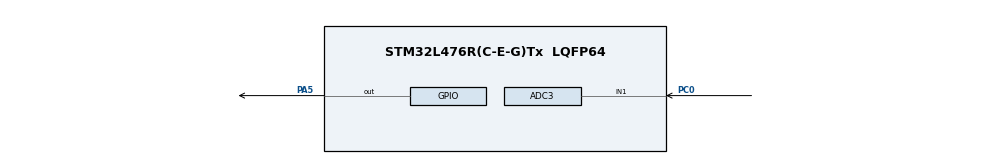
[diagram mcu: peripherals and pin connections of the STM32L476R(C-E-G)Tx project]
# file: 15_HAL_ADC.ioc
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ADC3.Channel-0\#ChannelRegularConversion=ADC_CHANNEL_1
ADC3.ContinuousConvMode=ENABLE
ADC3.NbrOfConversionFlag=1
ADC3.OffsetNumber-0\#ChannelRegularConversion=ADC_OFFSET_NONE
ADC3.Rank-0\#ChannelRegularConversion=1
ADC3.SamplingTime-0\#ChannelRegularConversion=ADC_SAMPLETIME_2CYCLES_5
Mcu.Family=STM32L4
Mcu.Name=STM32L476R(C-E-G)Tx
Mcu.Package=LQFP64
NVIC.PriorityGroup=NVIC_PRIORITYGROUP_4
PA5.Signal=GPIO_Output
PC0.Signal=ADCx_IN1
ProjectManager.HeapSize=0x200
ProjectManager.StackSize=0x400
ProjectManager.TargetToolchain=STM32CubeIDE
RCC.HSE_VALUE=8000000
RCC.HSI_VALUE=16000000
RCC.LSE_VALUE=32768
RCC.MSI_VALUE=4000000
RCC.VCOOutputFreq_Value=32000000
SH.ADCx_IN1.0=ADC3_IN1,IN1-Single-Ended
board=custom

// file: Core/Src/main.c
/* USER CODE BEGIN Header */
/**
  ******************************************************************************
  * @file           : main.c
  * @brief          : Main program body
  ******************************************************************************
  * @attention
  *
  * Copyright (c) 2026 STMicroelectronics.
  * All rights reserved.
  *
  * This software is licensed under terms that can be found in the LICENSE file
  * in the root directory of this software component.
  * If no LICENSE file comes with this software, it is provided AS-IS.
  *
  ******************************************************************************
  */
/* USER CODE END Header */
#include "main.h"

ADC_HandleTypeDef hadc3;

void SystemClock_Config(void);
static void MX_GPIO_Init(void);
static void MX_ADC3_Init(void);

/* USER CODE BEGIN 0 */
uint16_t adc_value = 0;
/* USER CODE END 0 */

int main(void)
{

  /* MCU Configuration--------------------------------------------------------*/

  /* Reset of all peripherals, Initializes the Flash interface and the Systick. */
  HAL_Init();

  /* Configure the system clock */
  SystemClock_Config();

  /* Initialize all configured peripherals */
  MX_GPIO_Init();
  MX_ADC3_Init();
  /* USER CODE BEGIN 2 */
  HAL_ADC_Start(&hadc3);
  /* USER CODE END 2 */

  /* Infinite loop */
  /* USER CODE BEGIN WHILE */
  while (1)
  {

	      HAL_ADC_PollForConversion(&hadc3, HAL_MAX_DELAY);

	      adc_value = HAL_ADC_GetValue(&hadc3);

    /* USER CODE END WHILE */

  }
}

void SystemClock_Config(void)
{
  RCC_OscInitTypeDef RCC_OscInitStruct = {0};
  RCC_ClkInitTypeDef RCC_ClkInitStruct = {0};

  /** Configure the main internal regulator output voltage
  */
  if (HAL_PWREx_ControlVoltageScaling(PWR_REGULATOR_VOLTAGE_SCALE1) != HAL_OK)
  {
    Error_Handler();
  }

  /** Initializes the RCC Oscillators according to the specified parameters
  * in the RCC_OscInitTypeDef structure.
  */
  RCC_OscInitStruct.OscillatorType = RCC_OSCILLATORTYPE_MSI;
  RCC_OscInitStruct.MSIState = RCC_MSI_ON;
  RCC_OscInitStruct.MSICalibrationValue = 0;
  RCC_OscInitStruct.MSIClockRange = RCC_MSIRANGE_6;
  RCC_OscInitStruct.PLL.PLLState = RCC_PLL_NONE;
  if (HAL_RCC_OscConfig(&RCC_OscInitStruct) != HAL_OK)
  {
    Error_Handler();
  }

  /** Initializes the CPU, AHB and APB buses clocks
  */
  RCC_ClkInitStruct.ClockType = RCC_CLOCKTYPE_HCLK|RCC_CLOCKTYPE_SYSCLK
                              |RCC_CLOCKTYPE_PCLK1|RCC_CLOCKTYPE_PCLK2;
  RCC_ClkInitStruct.SYSCLKSource = RCC_SYSCLKSOURCE_MSI;
  RCC_ClkInitStruct.AHBCLKDivider = RCC_SYSCLK_DIV1;
  RCC_ClkInitStruct.APB1CLKDivider = RCC_HCLK_DIV1;
  RCC_ClkInitStruct.APB2CLKDivider = RCC_HCLK_DIV1;

  if (HAL_RCC_ClockConfig(&RCC_ClkInitStruct, FLASH_LATENCY_0) != HAL_OK)
  {
    Error_Handler();
  }
}

static void MX_ADC3_Init(void)
{

  ADC_ChannelConfTypeDef sConfig = {0};

  /** Common config
  */
  hadc3.Instance = ADC3;
  hadc3.Init.ClockPrescaler = ADC_CLOCK_ASYNC_DIV1;
  hadc3.Init.Resolution = ADC_RESOLUTION_12B;
  hadc3.Init.DataAlign = ADC_DATAALIGN_RIGHT;
  hadc3.Init.ScanConvMode = ADC_SCAN_DISABLE;
  hadc3.Init.EOCSelection = ADC_EOC_SINGLE_CONV;
  hadc3.Init.LowPowerAutoWait = DISABLE;
  hadc3.Init.ContinuousConvMode = ENABLE;
  hadc3.Init.NbrOfConversion = 1;
  hadc3.Init.DiscontinuousConvMode = DISABLE;
  hadc3.Init.ExternalTrigConv = ADC_SOFTWARE_START;
  hadc3.Init.ExternalTrigConvEdge = ADC_EXTERNALTRIGCONVEDGE_NONE;
  hadc3.Init.DMAContinuousRequests = DISABLE;
  hadc3.Init.Overrun = ADC_OVR_DATA_PRESERVED;
  hadc3.Init.OversamplingMode = DISABLE;
  if (HAL_ADC_Init(&hadc3) != HAL_OK)
  {
    Error_Handler();
  }

  /** Configure Regular Channel
  */
  sConfig.Channel = ADC_CHANNEL_1;
  sConfig.Rank = ADC_REGULAR_RANK_1;
  sConfig.SamplingTime = ADC_SAMPLETIME_2CYCLES_5;
  sConfig.SingleDiff = ADC_SINGLE_ENDED;
  sConfig.OffsetNumber = ADC_OFFSET_NONE;
  sConfig.Offset = 0;
  if (HAL_ADC_ConfigChannel(&hadc3, &sConfig) != HAL_OK)
  {
    Error_Handler();
  }

}

static void MX_GPIO_Init(void)
{
  GPIO_InitTypeDef GPIO_InitStruct = {0};

  /* GPIO Ports Clock Enable */
  __HAL_RCC_GPIOC_CLK_ENABLE();
  __HAL_RCC_GPIOA_CLK_ENABLE();

  /*Configure GPIO pin Output Level */
  HAL_GPIO_WritePin(GPIOA, GPIO_PIN_5, GPIO_PIN_RESET);

  /*Configure GPIO pin : PA5 */
  GPIO_InitStruct.Pin = GPIO_PIN_5;
  GPIO_InitStruct.Mode = GPIO_MODE_OUTPUT_PP;
  GPIO_InitStruct.Pull = GPIO_NOPULL;
  GPIO_InitStruct.Speed = GPIO_SPEED_FREQ_LOW;
  HAL_GPIO_Init(GPIOA, &GPIO_InitStruct);

}

void Error_Handler(void)
{
  __disable_irq();
  while (1)
  {
  }
}
